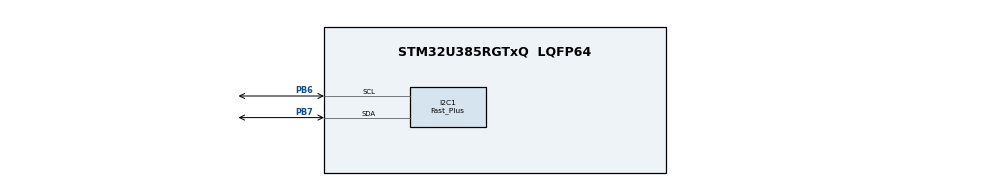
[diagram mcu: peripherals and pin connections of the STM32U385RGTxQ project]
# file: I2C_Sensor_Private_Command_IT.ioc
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CORTEX_M33_NS.userName=CORTEX_M33
I2C1.I2C_Fall_Time=2
I2C1.I2C_Rise_Time=26
I2C1.I2C_Speed_Mode=I2C_Fast_Plus
I2C1.NoStretchMode=I2C_NOSTRETCH_ENABLE
I2C1.Timing=0x0070123C
Mcu.Family=STM32U3
Mcu.Name=STM32U385RGTxQ
Mcu.Package=LQFP64
NVIC.I2C1_ER_IRQn=true\:0\:0\:false\:false\:true\:true\:true\:true
NVIC.I2C1_EV_IRQn=true\:0\:0\:false\:false\:true\:true\:true\:true
NVIC.PriorityGroup=NVIC_PRIORITYGROUP_4
PB6.GPIO_Pu=GPIO_PULLUP
PB6.Mode=I2C
PB6.Signal=I2C1_SCL
PB7.GPIO_Pu=GPIO_PULLUP
PB7.Mode=I2C
PB7.Signal=I2C1_SDA
ProjectManager.HeapSize=0x200
ProjectManager.StackSize=0x400
ProjectManager.TargetToolchain=EWARM V9.20
RCC.ADCFreq_Value=96000000
RCC.AHBFreq_Value=96000000
RCC.APB1Freq_Value=96000000
RCC.APB1TimFreq_Value=96000000
RCC.APB2Freq_Value=96000000
RCC.APB2TimFreq_Value=96000000
RCC.APB3Freq_Value=96000000
RCC.CortexFreq_Value=12000000
RCC.HCLKFreq_Value=96000000
RCC.HSE_VALUE=16000000
RCC.HSI48_VALUE=48000000
RCC.HSI_VALUE=16000000
RCC.LSE_VALUE=32768
RCC.LSIDIV_VALUE=32000
RCC.MSISDIV=RCC_MSI_DIV1
RCC.SYSCLKFreq_VALUE=96000000
RCC.USBFreq_Value=96000000
VP_ICACHE_VS_ICACHE.Mode=DirectMappedCache
VP_MEMORYMAP_VS_MEMORYMAP.Mode=CurAppReg
VP_PWR_VS_DBSignals.Mode=DisableDeadBatterySignals
VP_PWR_VS_LPOM.Mode=PowerOptimisation
VP_PWR_VS_SECSignals.Mode=Security/Privilege
board=custom

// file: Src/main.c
/* USER CODE BEGIN Header */
/**
  ******************************************************************************
  * @file    I2C/I2C_Sensor_Private_Command_IT/Src/main.c
  * @author  MCD Application Team
  * @brief   This sample code shows how to use STM32U3xx I2C HAL API to transmit
  *          and receive a data buffer with a communication process based on
  *          IT transfer.
  *          The communication is done using STM32U3xx Nucleo and
  *          X-NUCLEO-IKS4A1.
  ******************************************************************************
  * @attention
  *
  * Copyright (c) 2024 STMicroelectronics.
  * All rights reserved.
  *
  * This software is licensed under terms that can be found in the LICENSE file
  * in the root directory of this software component.
  * If no LICENSE file comes with this software, it is provided AS-IS.
  *
  ******************************************************************************
  */
/* USER CODE END Header */
#include "main.h"

I2C_HandleTypeDef hi2c1;

/* USER CODE BEGIN PV */
/* Variable used for LSM6DSV16X configuration, and reading data raw */
uint8_t CTRL1_XL_Register    = 0x10;         /* Address of accelerometer control register */
uint8_t OUT_TEMP_L_Register  = 0x20;         /* Address of temperature data output register */
uint8_t aLSM6DSV16X_Config[] = {0x06, 0x06}; /* Enable Accelerometer then Gyroscope */

/* Buffer used for reception */
uint8_t aRxBuffer[RXBUFFERSIZE];

/* Variable to display reading data */
uint32_t uwDisplayDelay   = 0U;
int16_t Temperature       = 0;
int16_t aGyroscope[3]     = {0};
int16_t aAccelerometer[3] = {0};

/* USER CODE END PV */

void SystemClock_Config(void);
static void MX_GPIO_Init(void);
static void MX_I2C1_Init(void);
static void MX_ICACHE_Init(void);
/* USER CODE BEGIN PFP */
/* Private function prototypes -----------------------------------------------*/
static void DisplayValue(uint8_t *pPrivateBuffer);
#if (defined (__GNUC__) && !defined(__ARMCC_VERSION))
extern void initialise_monitor_handles(void);
#endif

/* USER CODE END PFP */

int main(void)
{

  /* USER CODE BEGIN 1 */
#if (defined (__GNUC__) && !defined(__ARMCC_VERSION))
  initialise_monitor_handles();
  printf("Semihosting Test...\n\r");
#endif
  /* USER CODE END 1 */

  /* MCU Configuration--------------------------------------------------------*/

  /* Reset of all peripherals, Initializes the Flash interface and the Systick. */
  HAL_Init();

  /* Configure the system clock */
  SystemClock_Config();

  /* Initialize all configured peripherals */
  MX_GPIO_Init();
  MX_I2C1_Init();
  MX_ICACHE_Init();
  /* USER CODE BEGIN 2 */
  /* Configure LD2 */
  BSP_LED_Init(LD2);

  /* Configure User push-button */
  BSP_PB_Init(BUTTON_USER, BUTTON_MODE_GPIO);

  /*##-STEP1-#- Configure the Accelerometer then Gyroscope ###########################################################*/
  if (HAL_I2C_Mem_Write_IT(&hi2c1, LSM6DSV16X_STA, CTRL1_XL_Register, REGISTER_SIZE,
                           aLSM6DSV16X_Config, COUNTOF(aLSM6DSV16X_Config)) != HAL_OK)
  {
    /* Error_Handler() function is called when error occurs. */
    Error_Handler();
  }

  /*##- Wait for the end of the transfer #############################################################################*/
  /* Before starting a new communication transfer, you need to check the current
  state of the peripheral; if it's busy you need to wait for the end of current
  transfer before starting a new one.
  For simplicity reasons, this example is just waiting till the end of the
  transfer, but application may perform other tasks while transfer operation
  is ongoing. */
  while (HAL_I2C_GetState(&hi2c1) != HAL_I2C_STATE_READY)
  {
  }

  /* Wait for User push-button press before starting the Communication */
  while (BSP_PB_GetState(BUTTON_USER) != GPIO_PIN_SET)
  {
  }

  /* Delay to avoid that possible signal rebound is taken as button release */
  HAL_Delay(50);

  /* Wait for User push-button release before starting the Communication */
  while (BSP_PB_GetState(BUTTON_USER) != GPIO_PIN_RESET)
  {
  }
  /* USER CODE END 2 */

  /* Infinite loop */
  /* USER CODE BEGIN WHILE */
  while (1)
  {
    /*##- Start the read memory process ##############################################################################*/
    if (HAL_I2C_Mem_Read_IT(&hi2c1, LSM6DSV16X_STA, OUT_TEMP_L_Register, REGISTER_SIZE, aRxBuffer, RXBUFFERSIZE) != HAL_OK)
    {
      /* Error_Handler() function is called when error occurs. */
      Error_Handler();
    }

    /*##- Wait for the end of the transfer ###########################################################################*/
    /*  Before starting a new communication transfer, you need to check the current
    state of the peripheral; if it's busy you need to wait for the end of current
    transfer before starting a new one.
    For simplicity reasons, this example is just waiting till the end of the
    transfer, but application may perform other tasks while transfer operation
    is ongoing. */
    while (HAL_I2C_GetState(&hi2c1) != HAL_I2C_STATE_READY)
    {
    }

    /*##- Monitor the different value retrieve during Private communication */
    /*  At the end, of transfer, the application have retrieve all the data of
    the frame in an unique buffer, which must be unfill to retrieve the associated
    value */
    /* Display through external Terminal IO the value received */
    DisplayValue(&aRxBuffer[0]);

    /* Delay to fully display data */
    HAL_Delay(100);

    /* USER CODE END WHILE */

  }
}

void SystemClock_Config(void)
{
  RCC_OscInitTypeDef RCC_OscInitStruct = {0};
  RCC_ClkInitTypeDef RCC_ClkInitStruct = {0};

  /** Configure the System Power Supply
  */
  if (HAL_PWREx_ConfigSupply(PWR_SMPS_SUPPLY) != HAL_OK)
  {
    Error_Handler();
  }

  /** Enable Epod Booster
  */
  if (HAL_RCCEx_EpodBoosterClkConfig(RCC_EPODBOOSTER_SOURCE_MSIS, RCC_EPODBOOSTER_DIV1) != HAL_OK)
  {
    Error_Handler();
  }
  if (HAL_PWREx_EnableEpodBooster() != HAL_OK)
  {
    Error_Handler();
  }

  /** Configure the main internal regulator output voltage
  */
  if (HAL_PWREx_ControlVoltageScaling(PWR_REGULATOR_VOLTAGE_SCALE1) != HAL_OK)
  {
    Error_Handler();
  }

  /** Set Flash latency before increasing MSIS
  */
  __HAL_FLASH_SET_LATENCY(FLASH_LATENCY_2);

  /** Initializes the CPU, AHB and APB buses clocks
  */
  RCC_OscInitStruct.OscillatorType = RCC_OSCILLATORTYPE_MSIS;
  RCC_OscInitStruct.MSISState = RCC_MSI_ON;
  RCC_OscInitStruct.MSISSource = RCC_MSI_RC0;
  RCC_OscInitStruct.MSISDiv = RCC_MSI_DIV1;
  if (HAL_RCC_OscConfig(&RCC_OscInitStruct) != HAL_OK)
  {
    Error_Handler();
  }

  /** Initializes the CPU, AHB and APB buses clocks
  */
  RCC_ClkInitStruct.ClockType = RCC_CLOCKTYPE_HCLK|RCC_CLOCKTYPE_SYSCLK
                              |RCC_CLOCKTYPE_PCLK1|RCC_CLOCKTYPE_PCLK2
                              |RCC_CLOCKTYPE_PCLK3;
  RCC_ClkInitStruct.SYSCLKSource = RCC_SYSCLKSOURCE_MSIS;
  RCC_ClkInitStruct.AHBCLKDivider = RCC_SYSCLK_DIV1;
  RCC_ClkInitStruct.APB1CLKDivider = RCC_HCLK_DIV1;
  RCC_ClkInitStruct.APB2CLKDivider = RCC_HCLK_DIV1;
  RCC_ClkInitStruct.APB3CLKDivider = RCC_HCLK_DIV1;

  if (HAL_RCC_ClockConfig(&RCC_ClkInitStruct, FLASH_LATENCY_2) != HAL_OK)
  {
    Error_Handler();
  }
}

static void MX_I2C1_Init(void)
{

  hi2c1.Instance = I2C1;
  hi2c1.Init.Timing = 0x0070123C;
  hi2c1.Init.OwnAddress1 = 0;
  hi2c1.Init.AddressingMode = I2C_ADDRESSINGMODE_7BIT;
  hi2c1.Init.DualAddressMode = I2C_DUALADDRESS_DISABLE;
  hi2c1.Init.OwnAddress2 = 0;
  hi2c1.Init.OwnAddress2Masks = I2C_OA2_NOMASK;
  hi2c1.Init.GeneralCallMode = I2C_GENERALCALL_DISABLE;
  hi2c1.Init.NoStretchMode = I2C_NOSTRETCH_ENABLE;
  if (HAL_I2C_Init(&hi2c1) != HAL_OK)
  {
    Error_Handler();
  }

  /** Configure Analogue filter
  */
  if (HAL_I2CEx_ConfigAnalogFilter(&hi2c1, I2C_ANALOGFILTER_ENABLE) != HAL_OK)
  {
    Error_Handler();
  }

  /** Configure Digital filter
  */
  if (HAL_I2CEx_ConfigDigitalFilter(&hi2c1, 0) != HAL_OK)
  {
    Error_Handler();
  }

  /** I2C Fast mode Plus enable
  */
  if (HAL_I2CEx_ConfigFastModePlus(&hi2c1, I2C_FASTMODEPLUS_ENABLE) != HAL_OK)
  {
    Error_Handler();
  }

}

static void MX_ICACHE_Init(void)
{

  /** Enable instruction cache in 1-way (direct mapped cache)
  */
  if (HAL_ICACHE_ConfigAssociativityMode(ICACHE_1WAY) != HAL_OK)
  {
    Error_Handler();
  }
  if (HAL_ICACHE_Enable() != HAL_OK)
  {
    Error_Handler();
  }

}

static void MX_GPIO_Init(void)
{

  /* GPIO Ports Clock Enable */
  __HAL_RCC_GPIOB_CLK_ENABLE();

}

/* USER CODE BEGIN 4 */
/**
  * @brief  Memory Tx Transfer completed callback.
  * @param  hi2c Pointer to a I2C_HandleTypeDef structure that contains
  *                the configuration information for the specified I2C.
  * @retval None
  */
void HAL_I2C_MemTxCpltCallback(I2C_HandleTypeDef *I2cHandle)
{
  /* Toggle LD2: Transfer in transmission process is correct */
  BSP_LED_Toggle(LD2);
}

/**
  * @brief  Memory Rx Transfer completed callback.
  * @param  hi2c Pointer to a I2C_HandleTypeDef structure that contains
  *                the configuration information for the specified I2C.
  * @retval None
  */
void HAL_I2C_MemRxCpltCallback(I2C_HandleTypeDef *I2cHandle)
{
  /* Toggle LD2: Transfer in reception process is correct */
  BSP_LED_Toggle(LD2);
}

/**
  * @brief  I2C error callbacks.
  * @param  I2cHandle: I2C handle
  * @note   This example shows a simple way to report transfer error, and you can
  *         add your own implementation.
  * @retval None
  */
void HAL_I2C_ErrorCallback(I2C_HandleTypeDef *I2cHandle)
{
  /** Error_Handler() function is called when error occurs.
    * 1- When Slave doesn't acknowledge its address, Master restarts communication.
    * 2- When Master doesn't acknowledge the last data transferred, Slave doesn't care in this example.
    */
  if (HAL_I2C_GetError(I2cHandle) != HAL_I2C_ERROR_AF)
  {
    Error_Handler();
  }
}

/**
  * @brief  Display the different value retrieve during Communication.
  * @param  pPrivateBuffer Pointer to a receive Private buffer.
  * @retval None.
  */
static void DisplayValue(uint8_t *pPrivateBuffer)
{
  /* Temperature offset is 25 degree celsius, mean Temperature value 0 correspond to 25 Celsius degree */
#define TEMP_OFFSET 25

  /* Display the value measured each DISPLAY_REFRESH_DELAY */
  if (HAL_GetTick() >= (uwDisplayDelay + DISPLAY_REFRESH_DELAY))
  {
    Temperature = TEMP_OFFSET + (((int16_t)(((int16_t)aRxBuffer[1] * 256) + (int16_t)aRxBuffer[0])) / 100);

    printf("\n\r----------------LSM6DSV16X Measurement----------------\n\r");
    printf("Temperature (Celsius degree): %d \n\r", Temperature);

    aGyroscope[0] = (int16_t)aRxBuffer[3];
    aGyroscope[0] = (aGyroscope[0] * 256) + (int16_t)aRxBuffer[2];
    aGyroscope[1] = (int16_t)aRxBuffer[5];
    aGyroscope[1] = (aGyroscope[1] * 256) + (int16_t)aRxBuffer[4];
    aGyroscope[2] = (int16_t)aRxBuffer[7];
    aGyroscope[2] = (aGyroscope[2] * 256) + (int16_t)aRxBuffer[6];

    printf("GYR_X: %d, GYR_Y: %d, GYR_Z: %d\r\n", (int)aGyroscope[0], (int)aGyroscope[1], (int)aGyroscope[2]);

    aAccelerometer[0] = (int16_t)aRxBuffer[9];
    aAccelerometer[0] = (aAccelerometer[0] * 256) + (int16_t)aRxBuffer[8];
    aAccelerometer[1] = (int16_t)aRxBuffer[11];
    aAccelerometer[1] = (aAccelerometer[1] * 256) + (int16_t)aRxBuffer[10];
    aAccelerometer[2] = (int16_t)aRxBuffer[13];
    aAccelerometer[2] = (aAccelerometer[2] * 256) + (int16_t)aRxBuffer[12];

    printf("ACC_X: %d, ACC_Y: %d, ACC_Z: %d\r\n", (int)aAccelerometer[0], (int)aAccelerometer[1], (int)aAccelerometer[2]);

    uwDisplayDelay+=DISPLAY_REFRESH_DELAY;
  }
}

/* USER CODE END 4 */

void Error_Handler(void)
{
  /* USER CODE BEGIN Error_Handler_Debug */
  /* Error if LD2 is slowly blinking (1 sec. period) */
  while (1)
  {
    BSP_LED_Toggle(LD2);
    HAL_Delay(1000);
  }
  /* USER CODE END Error_Handler_Debug */
}
#ifdef USE_FULL_ASSERT
/**
  * @brief  Reports the name of the source file and the source line number
  *         where the assert_param error has occurred.
  * @param  file: pointer to the source file name
  * @param  line: assert_param error line source number
  * @retval None
  */
void assert_failed(uint8_t *file, uint32_t line)
{
  /* USER CODE BEGIN 6 */
  /* User can add his own implementation to report the file name and line number,
    ex: printf("Wrong parameters value: file %s on line %d\r\n", file, line) */
  /* Infinite Loop */
  while(1)
  {
  }
  /* USER CODE END 6 */
}
#endif /* USE_FULL_ASSERT */
